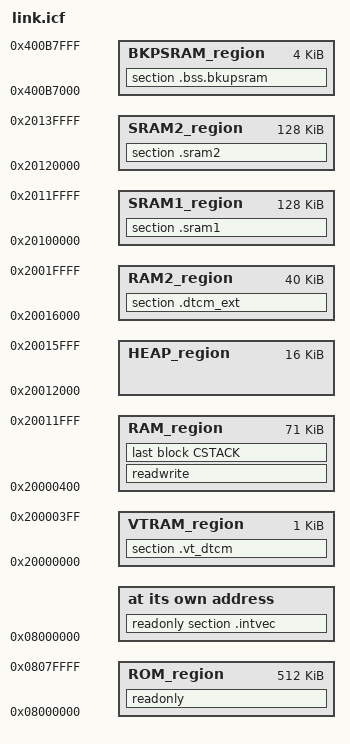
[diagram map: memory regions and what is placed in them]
/*###ICF### Section handled by ICF editor, don't touch! ****/
/*-Editor annotation file-*/
/* IcfEditorFile="$TOOLKIT_DIR$\config\ide\IcfEditor\cortex_v1_0.xml" */
/*-Specials-*/
define symbol __ICFEDIT_intvec_start__ = 0x08000000;
/*-Memory Regions-*/
define symbol __ICFEDIT_region_ROM_start__   = 0x08000000;
define symbol __ICFEDIT_region_ROM_end__     = 0x0807FFFF;
define symbol __ICFEDIT_region_RAM_start__   = 0x20000400;
define symbol __ICFEDIT_region_RAM_end__     = 0x20011FFF;
define symbol __ICFEDIT_region_VTRAM_start__ = 0x20000000;
define symbol __ICFEDIT_region_VTRAM_end__   = 0x200003FF;
define symbol __ICFEDIT_region_HEAP_start__  = 0x20012000;
define symbol __ICFEDIT_region_HEAP_end__    = 0x20015FFF;
define symbol __ICFEDIT_region_RAM2_start__  = 0x20016000;
define symbol __ICFEDIT_region_RAM2_end__    = 0x2001FFFF;
define symbol __ICFEDIT_region_SRAM1_start__ = 0x20100000;
define symbol __ICFEDIT_region_SRAM1_end__   = 0x2011FFFF;
define symbol __ICFEDIT_region_SRAM2_start__ = 0x20120000;
define symbol __ICFEDIT_region_SRAM2_end__   = 0x2013FFFF;
define symbol __ICFEDIT_region_BKPSRAM_start__ = 0x400B7000;
define symbol __ICFEDIT_region_BKPSRAM_end__   = 0x400B7FFF;
/*-Sizes-*/
define symbol __ICFEDIT_size_cstack__ = 0x1000;
define symbol __ICFEDIT_size_heap__   = 0x0000;
/**** End of ICF editor section. ###ICF###*/

define memory mem with size = 4G;

define region ROM_region    = mem:[from __ICFEDIT_region_ROM_start__ to __ICFEDIT_region_ROM_end__];
define region RAM_region    = mem:[from __ICFEDIT_region_RAM_start__ to __ICFEDIT_region_RAM_end__];
define region VTRAM_region  = mem:[from __ICFEDIT_region_VTRAM_start__ to __ICFEDIT_region_VTRAM_end__];
define region HEAP_region   = mem:[from __ICFEDIT_region_HEAP_start__ to __ICFEDIT_region_HEAP_end__];
define region RAM2_region   = mem:[from __ICFEDIT_region_RAM2_start__ to __ICFEDIT_region_RAM2_end__];
define region SRAM1_region  = mem:[from __ICFEDIT_region_SRAM1_start__ to __ICFEDIT_region_SRAM1_end__];
define region SRAM2_region  = mem:[from __ICFEDIT_region_SRAM2_start__ to __ICFEDIT_region_SRAM2_end__];
define region BKPSRAM_region = mem:[from __ICFEDIT_region_BKPSRAM_start__ to __ICFEDIT_region_BKPSRAM_end__];

define block CSTACK with alignment = 8, size = __ICFEDIT_size_cstack__ { };

initialize by copy { readwrite };
do not initialize  { section .noinit, section .bss.bkupsram };

define exported symbol Image$$RW_RT_HEAD$$Base  = __ICFEDIT_region_HEAP_start__;
define exported symbol Image$$RW_RT_HEAD$$Limit = __ICFEDIT_region_HEAP_start__;
define exported symbol Image$$RW_RT_HEAD$$End   = __ICFEDIT_region_HEAP_end__ + 1;

place at address mem:__ICFEDIT_intvec_start__ { readonly section .intvec };

place in ROM_region    { readonly };
place in RAM_region    { readwrite, last block CSTACK };
place in VTRAM_region  { section .vt_dtcm };
place in RAM2_region   { section .dtcm_ext };
place in SRAM1_region  { section .sram1 };
place in SRAM2_region  { section .sram2 };
place in BKPSRAM_region { section .bss.bkupsram };
